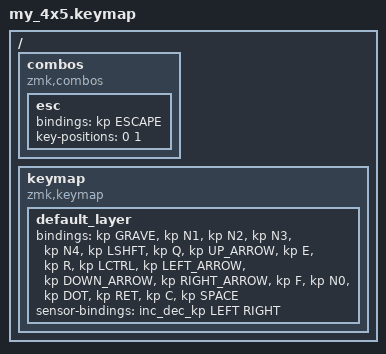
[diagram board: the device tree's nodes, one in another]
#include <behaviors.dtsi>
#include <dt-bindings/zmk/keys.h>

/ {
    combos {
        compatible = "zmk,combos";

        esc {
            bindings = <&kp ESCAPE>;
            key-positions = <0 1>;
        };
    };

    keymap {
        compatible = "zmk,keymap";

        default_layer {
            bindings = <
&kp GRAVE  &kp N1  &kp N2  &kp N3  &kp N4  &kp LSHFT  &kp Q  &kp UP_ARROW  &kp E  &kp R  &kp LCTRL  &kp LEFT_ARROW  &kp DOWN_ARROW  &kp RIGHT_ARROW  &kp F  &kp N0  &kp DOT  &kp RET  &kp C  &kp SPACE
            >;

            /* 엔코더 회전: 왼쪽/오른쪽 화살표 */

            sensor-bindings = <&inc_dec_kp LEFT RIGHT>;
        };
    };
};
